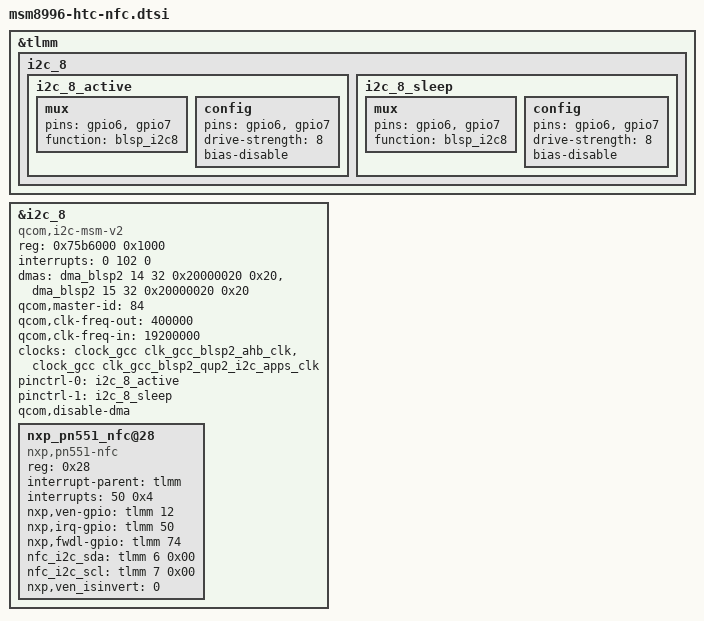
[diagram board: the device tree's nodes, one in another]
/* Copyright (c) 2016, The Linux Foundation. All rights reserved.
 *
 * This program is free software; you can redistribute it and/or modify
 * it under the terms of the GNU General Public License version 2 and
 * only version 2 as published by the Free Software Foundation.
 *
 * This program is distributed in the hope that it will be useful,
 * but WITHOUT ANY WARRANTY; without even the implied warranty of
 * MERCHANTABILITY or FITNESS FOR A PARTICULAR PURPOSE.  See the
 * GNU General Public License for more details.
 */

&tlmm {
	i2c_8 {
		i2c_8_active: i2c_8_active {
			mux {
				pins = "gpio6", "gpio7";
				function = "blsp_i2c8";
			};
			config {
				pins = "gpio6", "gpio7";
				drive-strength = <8>;
				bias-disable;
			};
		};

		i2c_8_sleep: i2c_8_sleep {
			mux {
				pins = "gpio6", "gpio7";
				function = "blsp_i2c8";
			};
			config {
				pins = "gpio6", "gpio7";
				drive-strength = <8>;
				bias-disable;
			};
		};
	};
};

&i2c_8 {
	/delete-node/ nq@28;
};

&i2c_8 {
	compatible = "qcom,i2c-msm-v2";
	#address-cells = <1>;
	#size-cells = <0>;
	reg-names = "qup_phys_addr";
	reg = <0x75b6000 0x1000>;
	interrupt-names = "qup_irq";
	interrupts = <0 102 0>;
	dmas = <&dma_blsp2 14 32 0x20000020 0x20>,
		<&dma_blsp2 15 32 0x20000020 0x20>;
	dma-names = "tx", "rx";
	qcom,master-id = <84>;
	qcom,clk-freq-out = <400000>;
	qcom,clk-freq-in  = <19200000>;
	clock-names = "iface_clk", "core_clk";
	clocks = <&clock_gcc clk_gcc_blsp2_ahb_clk>,
		<&clock_gcc clk_gcc_blsp2_qup2_i2c_apps_clk>;
	pinctrl-names = "i2c_active", "i2c_sleep";
	pinctrl-0 = <&i2c_8_active>;
	pinctrl-1 = <&i2c_8_sleep>;
	qcom,disable-dma;
	nxp_pn551_nfc@28 {
		compatible = "nxp,pn551-nfc";
		reg = <0x28>;
		interrupt-parent = <&tlmm>;
		interrupts = <50 0x4>;
		nxp,ven-gpio = <&tlmm 12 0x00>;
		nxp,irq-gpio = <&tlmm 50 0x00>;
		nxp,fwdl-gpio = <&tlmm 74 0x00>;
		nfc_i2c_sda = <&tlmm 6 0x00>;
		nfc_i2c_scl = <&tlmm 7 0x00>;
		nxp,ven_isinvert = <0>;
       };
};
